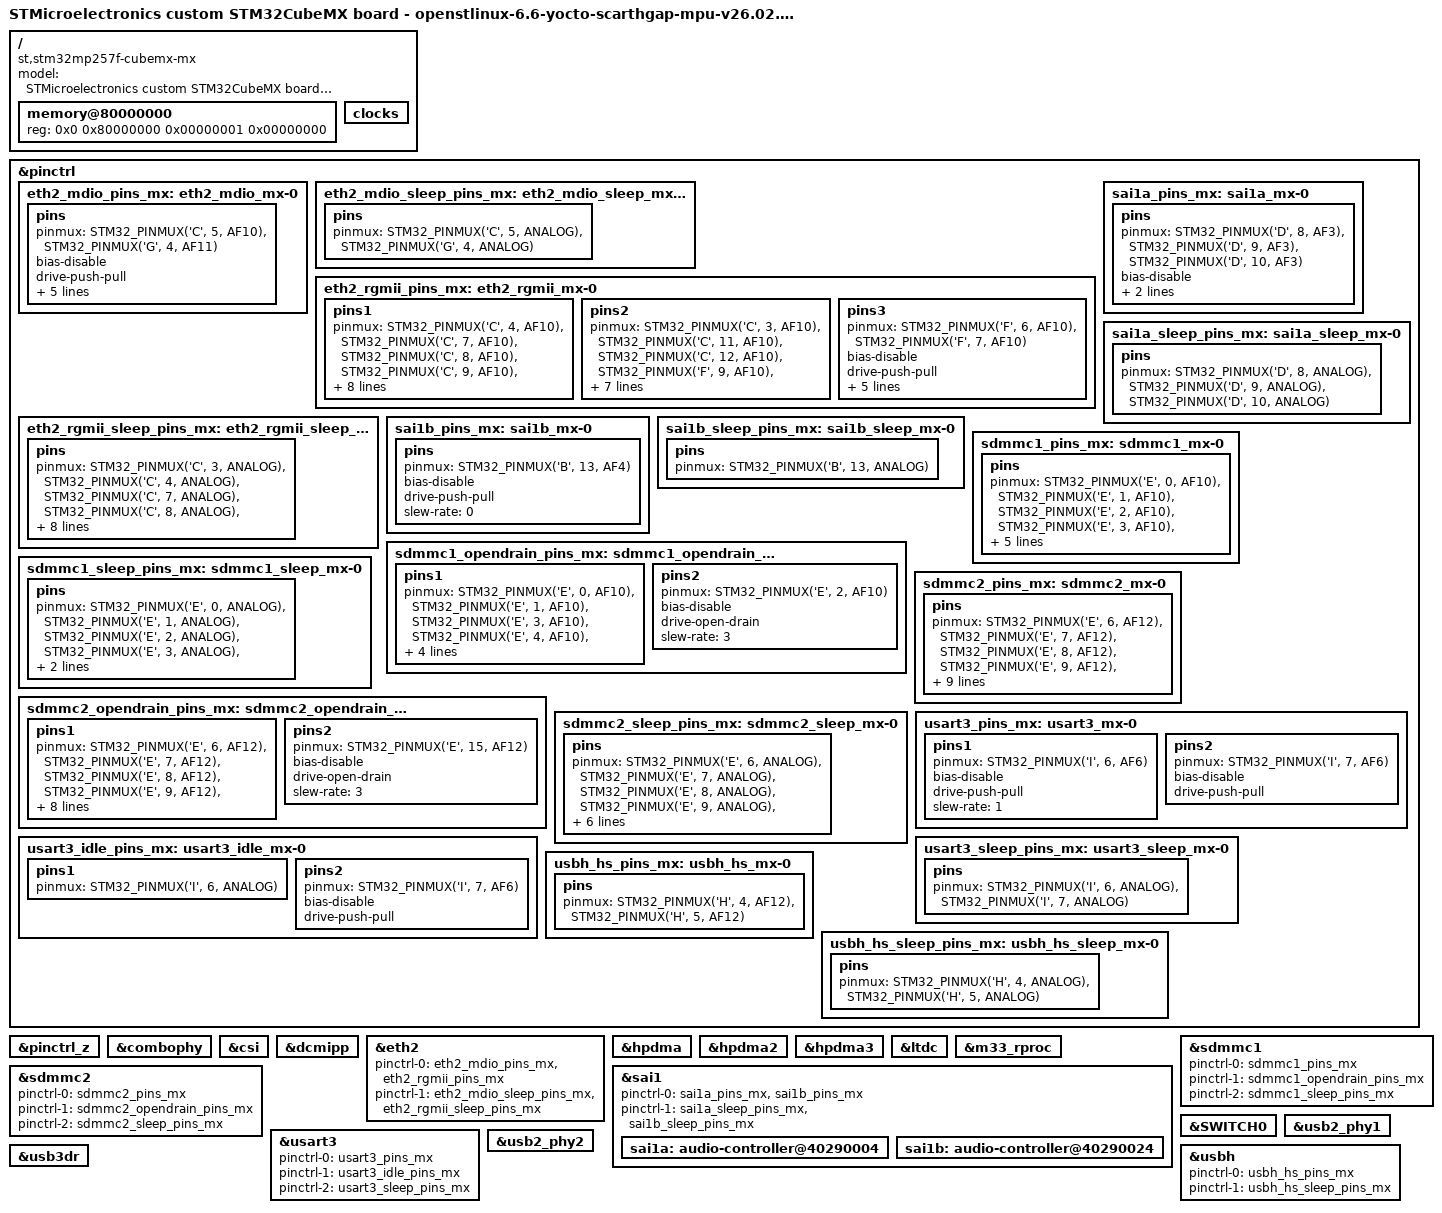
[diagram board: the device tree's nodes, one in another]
// SPDX-License-Identifier: (GPL-2.0-only OR BSD-3-Clause)
/*
 * Copyright (C) 2026, STMicroelectronics - All Rights Reserved
 * Author: STM32CubeMX code generation for STMicroelectronics.
 */

/* For more information on Device Tree configuration, please refer to
 * https://wiki.st.com/stm32mpu/wiki/Category:Device_tree_configuration
 */

/dts-v1/;

#include <dt-bindings/pinctrl/stm32-pinfunc.h>
#include "stm32mp257.dtsi"
#include "stm32mp25xf.dtsi"
#include "stm32mp257f-cubemx-mx-resmem.dtsi"
#include "stm32mp25xxak-pinctrl.dtsi"

/* USER CODE BEGIN includes */
/* USER CODE END includes */

/ {
	model = "STMicroelectronics custom STM32CubeMX board - openstlinux-6.6-yocto-scarthgap-mpu-v26.02.18";
	compatible = "st,stm32mp257f-cubemx-mx", "st,stm32mp257";

	memory@80000000 {
		device_type = "memory";
		reg = <0x0 0x80000000 0x00000001 0x00000000>;

		/* USER CODE BEGIN memory */
		/* USER CODE END memory */
	};

	/* USER CODE BEGIN root */
	/* USER CODE END root */

	clocks{

		/* USER CODE BEGIN clocks */
		/* USER CODE END clocks */
	};

}; /*root*/

&pinctrl {

	eth2_mdio_pins_mx: eth2_mdio_mx-0 {
		pins {
			pinmux = <STM32_PINMUX('C', 5, AF10)>, /* ETH2_MDIO */
					 <STM32_PINMUX('G', 4, AF11)>; /* ETH2_MDC */
			bias-disable;
			drive-push-pull;
			slew-rate = <3>;
			st,io-clk-edge = <0>;
			st,io-retime = <0>;
			st,io-delay-path = <0>;
			st,io-delay = <0>;
		};
	};

	eth2_mdio_sleep_pins_mx: eth2_mdio_sleep_mx-0 {
		pins {
			pinmux = <STM32_PINMUX('C', 5, ANALOG)>, /* ETH2_MDIO */
					 <STM32_PINMUX('G', 4, ANALOG)>; /* ETH2_MDC */
		};
	};

	eth2_rgmii_pins_mx: eth2_rgmii_mx-0 {
		pins1 {
			pinmux = <STM32_PINMUX('C', 4, AF10)>, /* ETH2_RGMII_TX_CTL */
					 <STM32_PINMUX('C', 7, AF10)>, /* ETH2_RGMII_TXD0 */
					 <STM32_PINMUX('C', 8, AF10)>, /* ETH2_RGMII_TXD1 */
					 <STM32_PINMUX('C', 9, AF10)>, /* ETH2_RGMII_TXD2 */
					 <STM32_PINMUX('C', 10, AF10)>; /* ETH2_RGMII_TXD3 */
			bias-disable;
			drive-push-pull;
			slew-rate = <3>;
			st,io-clk-edge = <1>;
			st,io-retime = <1>;
			st,io-delay-path = <0>;
			st,io-delay = <0>;
		};
		pins2 {
			pinmux = <STM32_PINMUX('C', 3, AF10)>, /* ETH2_RGMII_RX_CTL */
					 <STM32_PINMUX('C', 11, AF10)>, /* ETH2_RGMII_RXD3 */
					 <STM32_PINMUX('C', 12, AF10)>, /* ETH2_RGMII_RXD1 */
					 <STM32_PINMUX('F', 9, AF10)>, /* ETH2_RGMII_RXD2 */
					 <STM32_PINMUX('G', 0, AF10)>; /* ETH2_RGMII_RXD0 */
			bias-disable;
			drive-push-pull;
			st,io-clk-edge = <1>;
			st,io-retime = <1>;
			st,io-delay-path = <0>;
			st,io-delay = <0>;
		};
		pins3 {
			pinmux = <STM32_PINMUX('F', 6, AF10)>, /* ETH2_RGMII_RX_CLK */
					 <STM32_PINMUX('F', 7, AF10)>; /* ETH2_RGMII_GTX_CLK */
			bias-disable;
			drive-push-pull;
			slew-rate = <3>;
			st,io-clk-edge = <0>;
			st,io-retime = <0>;
			st,io-delay-path = <0>;
			st,io-delay = <0>;
		};
	};

	eth2_rgmii_sleep_pins_mx: eth2_rgmii_sleep_mx-0 {
		pins {
			pinmux = <STM32_PINMUX('C', 3, ANALOG)>, /* ETH2_RGMII_RX_CTL */
					 <STM32_PINMUX('C', 4, ANALOG)>, /* ETH2_RGMII_TX_CTL */
					 <STM32_PINMUX('C', 7, ANALOG)>, /* ETH2_RGMII_TXD0 */
					 <STM32_PINMUX('C', 8, ANALOG)>, /* ETH2_RGMII_TXD1 */
					 <STM32_PINMUX('C', 9, ANALOG)>, /* ETH2_RGMII_TXD2 */
					 <STM32_PINMUX('C', 10, ANALOG)>, /* ETH2_RGMII_TXD3 */
					 <STM32_PINMUX('C', 11, ANALOG)>, /* ETH2_RGMII_RXD3 */
					 <STM32_PINMUX('C', 12, ANALOG)>, /* ETH2_RGMII_RXD1 */
					 <STM32_PINMUX('F', 6, ANALOG)>, /* ETH2_RGMII_RX_CLK */
					 <STM32_PINMUX('F', 7, ANALOG)>, /* ETH2_RGMII_GTX_CLK */
					 <STM32_PINMUX('F', 9, ANALOG)>, /* ETH2_RGMII_RXD2 */
					 <STM32_PINMUX('G', 0, ANALOG)>; /* ETH2_RGMII_RXD0 */
		};
	};

	sai1a_pins_mx: sai1a_mx-0 {
		pins {
			pinmux = <STM32_PINMUX('D', 8, AF3)>, /* SAI1_FS_A */
					 <STM32_PINMUX('D', 9, AF3)>, /* SAI1_SD_A */
					 <STM32_PINMUX('D', 10, AF3)>; /* SAI1_SCK_A */
			bias-disable;
			drive-push-pull;
			slew-rate = <0>;
		};
	};

	sai1a_sleep_pins_mx: sai1a_sleep_mx-0 {
		pins {
			pinmux = <STM32_PINMUX('D', 8, ANALOG)>, /* SAI1_FS_A */
					 <STM32_PINMUX('D', 9, ANALOG)>, /* SAI1_SD_A */
					 <STM32_PINMUX('D', 10, ANALOG)>; /* SAI1_SCK_A */
		};
	};

	sai1b_pins_mx: sai1b_mx-0 {
		pins {
			pinmux = <STM32_PINMUX('B', 13, AF4)>; /* SAI1_SD_B */
			bias-disable;
			drive-push-pull;
			slew-rate = <0>;
		};
	};

	sai1b_sleep_pins_mx: sai1b_sleep_mx-0 {
		pins {
			pinmux = <STM32_PINMUX('B', 13, ANALOG)>; /* SAI1_SD_B */
		};
	};

	sdmmc1_pins_mx: sdmmc1_mx-0 {
		pins {
			pinmux = <STM32_PINMUX('E', 0, AF10)>, /* SDMMC1_D2 */
					 <STM32_PINMUX('E', 1, AF10)>, /* SDMMC1_D3 */
					 <STM32_PINMUX('E', 2, AF10)>, /* SDMMC1_CMD */
					 <STM32_PINMUX('E', 3, AF10)>, /* SDMMC1_CK */
					 <STM32_PINMUX('E', 4, AF10)>, /* SDMMC1_D0 */
					 <STM32_PINMUX('E', 5, AF10)>; /* SDMMC1_D1 */
			bias-disable;
			drive-push-pull;
			slew-rate = <3>;
		};
	};

	sdmmc1_opendrain_pins_mx: sdmmc1_opendrain_mx-0 {
		pins1 {
			pinmux = <STM32_PINMUX('E', 0, AF10)>, /* SDMMC1_D2 */
					 <STM32_PINMUX('E', 1, AF10)>, /* SDMMC1_D3 */
					 <STM32_PINMUX('E', 3, AF10)>, /* SDMMC1_CK */
					 <STM32_PINMUX('E', 4, AF10)>, /* SDMMC1_D0 */
					 <STM32_PINMUX('E', 5, AF10)>; /* SDMMC1_D1 */
			bias-disable;
			drive-push-pull;
			slew-rate = <3>;
		};
		pins2 {
			pinmux = <STM32_PINMUX('E', 2, AF10)>; /* SDMMC1_CMD */
			bias-disable;
			drive-open-drain;
			slew-rate = <3>;
		};
	};

	sdmmc1_sleep_pins_mx: sdmmc1_sleep_mx-0 {
		pins {
			pinmux = <STM32_PINMUX('E', 0, ANALOG)>, /* SDMMC1_D2 */
					 <STM32_PINMUX('E', 1, ANALOG)>, /* SDMMC1_D3 */
					 <STM32_PINMUX('E', 2, ANALOG)>, /* SDMMC1_CMD */
					 <STM32_PINMUX('E', 3, ANALOG)>, /* SDMMC1_CK */
					 <STM32_PINMUX('E', 4, ANALOG)>, /* SDMMC1_D0 */
					 <STM32_PINMUX('E', 5, ANALOG)>; /* SDMMC1_D1 */
		};
	};

	sdmmc2_pins_mx: sdmmc2_mx-0 {
		pins {
			pinmux = <STM32_PINMUX('E', 6, AF12)>, /* SDMMC2_D6 */
					 <STM32_PINMUX('E', 7, AF12)>, /* SDMMC2_D7 */
					 <STM32_PINMUX('E', 8, AF12)>, /* SDMMC2_D2 */
					 <STM32_PINMUX('E', 9, AF12)>, /* SDMMC2_D5 */
					 <STM32_PINMUX('E', 10, AF12)>, /* SDMMC2_D4 */
					 <STM32_PINMUX('E', 11, AF12)>, /* SDMMC2_D1 */
					 <STM32_PINMUX('E', 12, AF12)>, /* SDMMC2_D3 */
					 <STM32_PINMUX('E', 13, AF12)>, /* SDMMC2_D0 */
					 <STM32_PINMUX('E', 14, AF12)>, /* SDMMC2_CK */
					 <STM32_PINMUX('E', 15, AF12)>; /* SDMMC2_CMD */
			bias-disable;
			drive-push-pull;
			slew-rate = <3>;
		};
	};

	sdmmc2_opendrain_pins_mx: sdmmc2_opendrain_mx-0 {
		pins1 {
			pinmux = <STM32_PINMUX('E', 6, AF12)>, /* SDMMC2_D6 */
					 <STM32_PINMUX('E', 7, AF12)>, /* SDMMC2_D7 */
					 <STM32_PINMUX('E', 8, AF12)>, /* SDMMC2_D2 */
					 <STM32_PINMUX('E', 9, AF12)>, /* SDMMC2_D5 */
					 <STM32_PINMUX('E', 10, AF12)>, /* SDMMC2_D4 */
					 <STM32_PINMUX('E', 11, AF12)>, /* SDMMC2_D1 */
					 <STM32_PINMUX('E', 12, AF12)>, /* SDMMC2_D3 */
					 <STM32_PINMUX('E', 13, AF12)>, /* SDMMC2_D0 */
					 <STM32_PINMUX('E', 14, AF12)>; /* SDMMC2_CK */
			bias-disable;
			drive-push-pull;
			slew-rate = <3>;
		};
		pins2 {
			pinmux = <STM32_PINMUX('E', 15, AF12)>; /* SDMMC2_CMD */
			bias-disable;
			drive-open-drain;
			slew-rate = <3>;
		};
	};

	sdmmc2_sleep_pins_mx: sdmmc2_sleep_mx-0 {
		pins {
			pinmux = <STM32_PINMUX('E', 6, ANALOG)>, /* SDMMC2_D6 */
					 <STM32_PINMUX('E', 7, ANALOG)>, /* SDMMC2_D7 */
					 <STM32_PINMUX('E', 8, ANALOG)>, /* SDMMC2_D2 */
					 <STM32_PINMUX('E', 9, ANALOG)>, /* SDMMC2_D5 */
					 <STM32_PINMUX('E', 10, ANALOG)>, /* SDMMC2_D4 */
					 <STM32_PINMUX('E', 11, ANALOG)>, /* SDMMC2_D1 */
					 <STM32_PINMUX('E', 12, ANALOG)>, /* SDMMC2_D3 */
					 <STM32_PINMUX('E', 13, ANALOG)>, /* SDMMC2_D0 */
					 <STM32_PINMUX('E', 14, ANALOG)>, /* SDMMC2_CK */
					 <STM32_PINMUX('E', 15, ANALOG)>; /* SDMMC2_CMD */
		};
	};

	usart3_pins_mx: usart3_mx-0 {
		pins1 {
			pinmux = <STM32_PINMUX('I', 6, AF6)>; /* USART3_TX */
			bias-disable;
			drive-push-pull;
			slew-rate = <1>;
		};
		pins2 {
			pinmux = <STM32_PINMUX('I', 7, AF6)>; /* USART3_RX */
			bias-disable;
			drive-push-pull;
		};
	};

	usart3_idle_pins_mx: usart3_idle_mx-0 {
		pins1 {
			pinmux = <STM32_PINMUX('I', 6, ANALOG)>; /* USART3_TX */
		};
		pins2 {
			pinmux = <STM32_PINMUX('I', 7, AF6)>; /* USART3_RX */
			bias-disable;
			drive-push-pull;
		};
	};

	usart3_sleep_pins_mx: usart3_sleep_mx-0 {
		pins {
			pinmux = <STM32_PINMUX('I', 6, ANALOG)>, /* USART3_TX */
					 <STM32_PINMUX('I', 7, ANALOG)>; /* USART3_RX */
		};
	};

	usbh_hs_pins_mx: usbh_hs_mx-0 {
		pins {
			pinmux = <STM32_PINMUX('H', 4, AF12)>, /* USBH_HS_OVRCUR */
					 <STM32_PINMUX('H', 5, AF12)>; /* USBH_HS_VBUSEN */
		};
	};

	usbh_hs_sleep_pins_mx: usbh_hs_sleep_mx-0 {
		pins {
			pinmux = <STM32_PINMUX('H', 4, ANALOG)>, /* USBH_HS_OVRCUR */
					 <STM32_PINMUX('H', 5, ANALOG)>; /* USBH_HS_VBUSEN */
		};
	};

	/* USER CODE BEGIN pinctrl */
	/* USER CODE END pinctrl */
};

&pinctrl_z {

	/* USER CODE BEGIN pinctrl_z */
	/* USER CODE END pinctrl_z */
};

&combophy {
	status = "okay";

	/* USER CODE BEGIN combophy */
	/* USER CODE END combophy */
};

&csi {
	status = "okay";

	/* USER CODE BEGIN csi */
	/* USER CODE END csi */
};

&dcmipp {
	status = "okay";

	/* USER CODE BEGIN dcmipp */
	/* USER CODE END dcmipp */
};

&eth2 {
	pinctrl-names = "default", "sleep";
	pinctrl-0 = <&eth2_mdio_pins_mx>, <&eth2_rgmii_pins_mx>;
	pinctrl-1 = <&eth2_mdio_sleep_pins_mx>, <&eth2_rgmii_sleep_pins_mx>;
	status = "okay";

	/* USER CODE BEGIN eth2 */
	/* USER CODE END eth2 */
};

&hpdma {
	status = "okay";

	/* USER CODE BEGIN hpdma */
	/* USER CODE END hpdma */
};

&hpdma2 {
	status = "okay";

	/* USER CODE BEGIN hpdma2 */
	/* USER CODE END hpdma2 */
};

&hpdma3 {
	status = "okay";

	/* USER CODE BEGIN hpdma3 */
	/* USER CODE END hpdma3 */
};

&ltdc {
	status = "okay";

	/* USER CODE BEGIN ltdc */
	/* USER CODE END ltdc */
};

&m33_rproc {
	status = "okay";

	/* USER CODE BEGIN m33_rproc */
	/* USER CODE END m33_rproc */
};

&sai1 {
	pinctrl-names = "default", "sleep";
	pinctrl-0 = <&sai1a_pins_mx>, <&sai1b_pins_mx>;
	pinctrl-1 = <&sai1a_sleep_pins_mx>, <&sai1b_sleep_pins_mx>;
	status = "okay";

	/* USER CODE BEGIN sai1 */
	/* USER CODE END sai1 */

	sai1a:audio-controller@40290004{
		status = "okay";

		/* USER CODE BEGIN sai1a */
		/* USER CODE END sai1a */
	};

	sai1b:audio-controller@40290024{
		status = "okay";

		/* USER CODE BEGIN sai1b */
		/* USER CODE END sai1b */
	};
};

&sdmmc1 {
	pinctrl-names = "default", "opendrain", "sleep";
	pinctrl-0 = <&sdmmc1_pins_mx>;
	pinctrl-1 = <&sdmmc1_opendrain_pins_mx>;
	pinctrl-2 = <&sdmmc1_sleep_pins_mx>;
	status = "okay";

	/* USER CODE BEGIN sdmmc1 */
	/* USER CODE END sdmmc1 */
};

&sdmmc2 {
	pinctrl-names = "default", "opendrain", "sleep";
	pinctrl-0 = <&sdmmc2_pins_mx>;
	pinctrl-1 = <&sdmmc2_opendrain_pins_mx>;
	pinctrl-2 = <&sdmmc2_sleep_pins_mx>;
	status = "okay";

	/* USER CODE BEGIN sdmmc2 */
	/* USER CODE END sdmmc2 */
};

&SWITCH0 {
	status = "okay";

	/* USER CODE BEGIN SWITCH0 */
	/* USER CODE END SWITCH0 */
};

&usart3 {
	pinctrl-names = "default", "idle", "sleep";
	pinctrl-0 = <&usart3_pins_mx>;
	pinctrl-1 = <&usart3_idle_pins_mx>;
	pinctrl-2 = <&usart3_sleep_pins_mx>;
	status = "okay";

	/* USER CODE BEGIN usart3 */
	/* USER CODE END usart3 */
};

&usb2_phy1 {
	status = "okay";

	/* USER CODE BEGIN usb2_phy1 */
	/* USER CODE END usb2_phy1 */
};

&usb2_phy2 {
	status = "okay";

	/* USER CODE BEGIN usb2_phy2 */
	/* USER CODE END usb2_phy2 */
};

&usb3dr {
	status = "okay";

	/* USER CODE BEGIN usb3dr */
	/* USER CODE END usb3dr */
};

&usbh {
	pinctrl-names = "default", "sleep";
	pinctrl-0 = <&usbh_hs_pins_mx>;
	pinctrl-1 = <&usbh_hs_sleep_pins_mx>;
	status = "okay";

	/* USER CODE BEGIN usbh */
	/* USER CODE END usbh */
};

/* USER CODE BEGIN addons */
/* USER CODE END addons */

